VERSION "HNNBNNNYNNNNNNNNNNNNNNNNNNNNNNNNNNNNNNNNNN/4/%%%/4/'%**4NNN///"

NS_ :

BS_:

BU_: Airbag eCS

BO_ 64 Airbag_01: 8 Airbag
 SG_ Airbag_01_CRC : 0|8@1+ (1,0) [0|255] "" Vector__XXX
 SG_ Airbag_01_BZ : 8|4@1+ (1,0) [0|15] "" Vector__XXX
 SG_ AB_RGS_Anst : 12|4@1+ (1,0) [0|15] "" Vector__XXX
 SG_ AB_Front_Crash : 16|1@1+ (1,0) [0|1] "" Vector__XXX
 SG_ AB_Heck_Crash : 17|1@1+ (1,0) [0|1] "" Vector__XXX
 SG_ AB_SF_Crash : 18|1@1+ (1,0) [0|1] "" Vector__XXX
 SG_ AB_SB_Crash : 19|1@1+ (1,0) [0|1] "" Vector__XXX
 SG_ AB_Rollover_Crash : 20|1@1+ (1,0) [0|1] "" Vector__XXX
 SG_ AB_Crash_Int : 21|3@1+ (1,0) [0|7] ""  eCS
 SG_ AB_Lampe : 24|1@1+ (1,0) [0|1] "" Vector__XXX
 SG_ AB_Deaktiviert : 25|1@1+ (1,0) [0|1] "" Vector__XXX
 SG_ AB_VB_deaktiviert : 26|1@1+ (1,0) [0|1] "" Vector__XXX
 SG_ AB_Systemfehler : 27|1@1+ (1,0) [0|1] "" Vector__XXX
 SG_ AB_Diagnose : 28|1@1+ (1,0) [0|1] "" Vector__XXX
 SG_ AB_Stellgliedtest : 29|1@1+ (1,0) [0|1] "" Vector__XXX
 SG_ AB_Erh_Auf_VB : 30|2@1+ (1,0) [0|3] "" Vector__XXX
 SG_ AB_Gurtwarn_VF : 32|1@1+ (1,0) [0|1] "" Vector__XXX
 SG_ AB_Gurtwarn_VB : 33|1@1+ (1,0) [0|1] "" Vector__XXX
 SG_ AB_Anzeige_Fussg : 34|2@1+ (1,0) [0|3] "" Vector__XXX
 SG_ AB_Texte_AKS : 36|2@1+ (1,0) [0|3] "" Vector__XXX
 SG_ AB_PAO_Leuchte_Anf : 38|1@1+ (1,0) [0|1] "" Vector__XXX
 SG_ AB_MKB_gueltig : 39|1@1+ (1,0) [0|1] "" Vector__XXX
 SG_ AB_MKB_Anforderung : 40|1@1+ (1,0) [0|1] "" Vector__XXX
 SG_ AB_Versorgungsspannung : 41|1@1+ (1,0) [0|1] "" Vector__XXX
 SG_ AB_Deaktivierung_HV : 42|3@1+ (1,0) [0|7] "" Vector__XXX
 SG_ AB_EDR_Trigger : 45|2@1+ (1,0) [0|3] "" Vector__XXX
 SG_ AB_Belegung_VF : 47|2@1+ (1,0) [0|3] "" Vector__XXX
 SG_ AB_Gurtschloss_FA_ext : 49|3@1+ (1,0) [0|7] "" Vector__XXX
 SG_ AB_Gurtschloss_FA_ext_aktiv : 52|1@1+ (1,0) [0|1] "" Vector__XXX
 SG_ AB_eCS_Error : 53|1@1+ (1,0) [0|1] "" Vector__XXX
 SG_ ASM_Masterzeit_02 : 56|8@1+ (0.04,0) [0|10.16] "Unit_Secon" Vector__XXX

BO_ 1312 Airbag_02: 8 Airbag
 SG_ Airbag_02_CRC : 0|8@1+ (1,0) [0|255] "" Vector__XXX
 SG_ Airbag_02_BZ : 8|4@1+ (1,0) [0|15] "" Vector__XXX
 SG_ LoGeWa_Event_Kombiwarnung : 12|4@1+ (1,0) [0|15] "" Vector__XXX
 SG_ AB_Anforderung_eCall : 16|1@1+ (1,0) [0|1] "" Vector__XXX
 SG_ AB_Anprall_Seite_Beifahrer : 17|1@1+ (1,0) [0|1] "" Vector__XXX
 SG_ AB_Anprall_Rollover : 18|1@1+ (1,0) [0|1] "" Vector__XXX
 SG_ AB_Anprall_FGS : 19|1@1+ (1,0) [0|1] "" Vector__XXX
 SG_ AB_Anprall_Front_Beifahrer : 20|1@1+ (1,0) [0|1] "" Vector__XXX
 SG_ AB_Anprall_Front_Fahrer : 21|1@1+ (1,0) [0|1] "" Vector__XXX
 SG_ AB_Anprall_Heck_Beifahrer : 22|1@1+ (1,0) [0|1] "" Vector__XXX
 SG_ AB_Anprall_Heck_Fahrer : 23|1@1+ (1,0) [0|1] "" Vector__XXX
 SG_ AB_Wickelklappung_Reihe2_MI : 24|2@1+ (1,0) [0|3] "" Vector__XXX
 SG_ AB_Belegung_VB : 26|2@1+ (1,0) [0|3] "" Vector__XXX
 SG_ AB_Abschaltanf_SIH_BF : 28|1@1+ (1,0) [0|1] "" Vector__XXX
 SG_ AB_Anprall_Seite_Fahrer : 29|1@1+ (1,0) [0|1] "" Vector__XXX
 SG_ SC_PAO_Schriftzug_Anf : 30|2@1+ (1,0) [0|3] "" Vector__XXX
 SG_ SC_PAO_ON_Anf : 32|2@1+ (1,0) [0|3] "" Vector__XXX
 SG_ SC_PAO_OFF_Anf : 34|2@1+ (1,0) [0|3] "" Vector__XXX
 SG_ AB_Crashschwere : 36|3@1+ (1,0) [0|7] "" Vector__XXX
 SG_ AB_Anforderung_USM : 39|1@1+ (1,0) [0|1] "" Vector__XXX
 SG_ AB_Gurtschloss_FA : 40|2@1+ (1,0) [0|3] ""  eCS
 SG_ AB_Gurtschloss_BF : 42|2@1+ (1,0) [0|3] ""  eCS
 SG_ AB_Gurtschloss_Reihe2_FA : 44|2@1+ (1,0) [0|3] ""  eCS
 SG_ AB_Gurtschloss_Reihe2_MI : 46|2@1+ (1,0) [0|3] "" Vector__XXX
 SG_ AB_Gurtschloss_Reihe2_BF : 48|2@1+ (1,0) [0|3] ""  eCS
 SG_ AB_Gurtschloss_Reihe3_FA : 50|2@1+ (1,0) [0|3] ""  eCS
 SG_ AB_Gurtschloss_Reihe3_MI : 52|2@1+ (1,0) [0|3] "" Vector__XXX
 SG_ AB_Gurtschloss_Reihe3_BF : 54|2@1+ (1,0) [0|3] ""  eCS
 SG_ AB_Sitzpos_Sens_FA : 56|2@1+ (1,0) [0|3] "" Vector__XXX
 SG_ AB_Sitzpos_Sens_BF : 58|2@1+ (1,0) [0|3] "" Vector__XXX
 SG_ AB_Wickelklappung_Reihe2_BF : 60|2@1+ (1,0) [0|3] "" Vector__XXX
 SG_ AB_Wickelklappung_Reihe2_FA : 62|2@1+ (1,0) [0|3] "" Vector__XXX

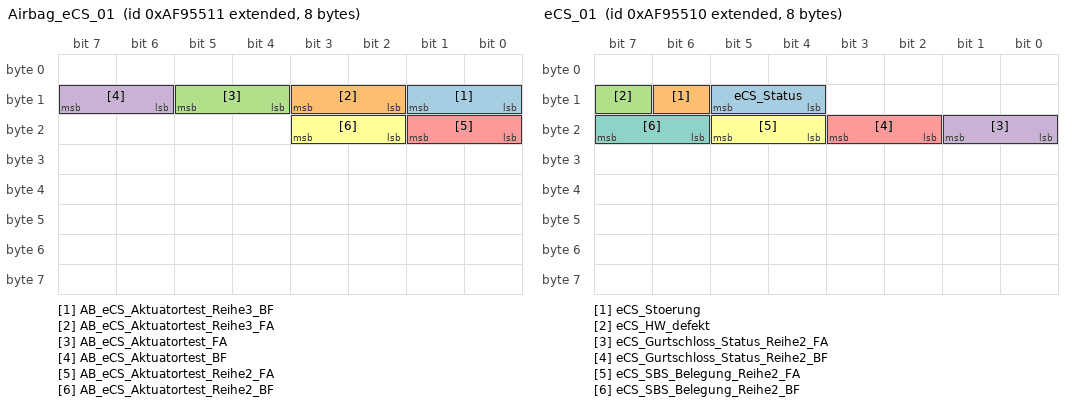
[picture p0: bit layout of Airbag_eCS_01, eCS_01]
BO_ 2331596049 Airbag_eCS_01: 8 Airbag
 SG_ AB_eCS_Aktuatortest_Reihe3_BF : 8|2@1+ (1,0) [0|3] ""  eCS
 SG_ AB_eCS_Aktuatortest_Reihe3_FA : 10|2@1+ (1,0) [0|3] ""  eCS
 SG_ AB_eCS_Aktuatortest_FA : 12|2@1+ (1,0) [0|3] ""  eCS
 SG_ AB_eCS_Aktuatortest_BF : 14|2@1+ (1,0) [0|3] ""  eCS
 SG_ AB_eCS_Aktuatortest_Reihe2_FA : 16|2@1+ (1,0) [0|3] ""  eCS
 SG_ AB_eCS_Aktuatortest_Reihe2_BF : 18|2@1+ (1,0) [0|3] ""  eCS

BO_ 2549891590 DIA_eCS_Req: 8 Airbag
 SG_ DIA_eCS_Req_Data : 0|64@1+ (1,0) [0|1.84467440737096E+019] ""  eCS

BO_ 2621456902 DIA_eCS_Req_FD: 64 Airbag
 SG_ DIA_eCS_Req_FD_Data : 0|512@1+ (1,0) [0|1.34078079299426E+154] ""  eCS

BO_ 2550022662 DIA_eCS_Resp: 8 eCS
 SG_ DIA_eCS_Resp_Data : 0|64@1+ (1,0) [0|1.84467440737096E+019] ""  Airbag

BO_ 2621587974 DIA_eCS_Resp_FD: 64 eCS
 SG_ DIA_eCS_Resp_FD_Data : 0|512@1+ (1,0) [0|1.34078079299426E+154] ""  Airbag

BO_ 2621460998 Diag_eCS_Req_FD: 64 Airbag
 SG_ Diag_eCS_Req_FD_Data : 0|512@1+ (1,0) [0|1.34078079299426E+154] ""  eCS

BO_ 2621592070 Diag_eCS_Resp_FD: 64 eCS
 SG_ Diag_eCS_Resp_FD_Data : 0|512@1+ (1,0) [0|1.34078079299426E+154] ""  Airbag

BO_ 2331596048 eCS_01: 8 eCS
 SG_ eCS_Status : 12|2@1+ (1,0) [0|3] ""  Airbag
 SG_ eCS_Stoerung : 14|1@1+ (1,0) [0|1] ""  Airbag
 SG_ eCS_HW_defekt : 15|1@1+ (1,0) [0|1] ""  Airbag
 SG_ eCS_Gurtschloss_Status_Reihe2_FA : 16|2@1+ (1,0) [0|3] ""  Airbag
 SG_ eCS_Gurtschloss_Status_Reihe2_BF : 18|2@1+ (1,0) [0|3] ""  Airbag
 SG_ eCS_SBS_Belegung_Reihe2_FA : 20|2@1+ (1,0) [0|3] ""  Airbag
 SG_ eCS_SBS_Belegung_Reihe2_BF : 22|2@1+ (1,0) [0|3] ""  Airbag

BO_ 2621469190 OBDC_SSN_eCS_Req_FD: 64 Airbag
 SG_ OBDC_SSN_eCS_Req_FD_Data : 0|512@1+ (1,0) [0|1.34078079299426E+154] ""  eCS

BO_ 2621600262 OBDC_SSN_eCS_Resp_FD: 64 eCS
 SG_ OBDC_SSN_eCS_Resp_FD_Data : 0|512@1+ (1,0) [0|1.34078079299426E+154] ""  Airbag

CM_ "Airbag_SUBCANFD_V14.08.02E Generated by BUSNETNG Produktiv 9.24.6";
CM_ BU_ Airbag "Airbag E3_Volumen";
CM_ SG_ 64 Airbag_01_CRC "Für MLB:
'Berechnung siehe Lastenheft 'Kommunikationsabsicherung für FlexRay und CAN''

Ab MQB und MLBevo:
'Berechnung siehe Lastenheft 'End-to-End Kommunikationsabsicherung''

Endwerte siehe Begleitdokument 'S-PDU Kennungsfolgen'";
CM_ SG_ 64 AB_RGS_Anst "PreCrash-Ansteuerung reversibler Gurtstraffer (Aktivierung und Kraftniveau)

10xx = deaktiviert";
CM_ SG_ 64 AB_Front_Crash "Bit wird bei Überschreitung der Gurtstraffer-, US- und RdW-Schwelle gesetzt";
CM_ SG_ 64 AB_Heck_Crash "Wird für alle neu anlaufenden Projekte umgesetzt: AB8.4, Audi8/VW8";
CM_ SG_ 64 AB_SF_Crash "Z.Zt. nur in Verbindung mit Crash-Intensität >= 100b (Kraftstoffpumpenabschaltung) verwendet.";
CM_ SG_ 64 AB_SB_Crash "Z.Zt. nur in Verbindung mit Crash-Intensität >= 100b (Kraftstoffpumpenabschaltung) verwendet.
";
CM_ SG_ 64 AB_Rollover_Crash "Wird im B6/B7 Cabrio und New Beetle Cabrio bedient. ";
CM_ SG_ 64 AB_Crash_Int "Crash_Intensität_1 = fahrzeugabhängige Reaktionen im Crash
Crash_Intensität_2 = fahrzeugabhängige Reaktionen im Crash
Crash_Intensität_3 = fahrzeugabhängige Reaktionen im Crash

Die jeweiligen fahrzeugabhängigen Reaktionen im Crash sind in einem separ";
CM_ SG_ 64 AB_Lampe "Sicherheitswarnlampe im Kombi wird vom Airbag-SG angesteuert; Zustand der Lampe wird auf dem CAN-Bus ausgegeben (auch Blinkinformation).";
CM_ SG_ 64 AB_Deaktiviert "Airbag oder Gurtstraffer wurden per Anpassung deaktiviert: Aktualisierung erst nach Selbsttest";
CM_ SG_ 64 AB_VB_deaktiviert "Als Option vorgehalten, Beifahrerairbag wurden per Schlüsselschalter oder Insassenerkennung deaktiviert";
CM_ SG_ 64 AB_Systemfehler "Systemfehler Ggf. wird Warnlampe dauernd eingeschaltet.";
CM_ SG_ 64 AB_Diagnose "Airbag in Diagnose";
CM_ SG_ 64 AB_Stellgliedtest "Information, ob Airbag im Stellgliedtest ist, um eine Notrufauflösung beim Stellgliedtest zu verhindern";
CM_ SG_ 64 AB_Erh_Auf_VB "Der Fahrer soll bei einem Statuswechsel des Beifahrerairbags (ausgelöst durch die Beifahrerinsassenerkennung oder den Schlüsselschloßschalter) aufmerksam gemacht werden durch eine Anzeige im Kombi. Nur Audi: gültig für: AB2 (4-Türer AU352), B7, C6, D3";
CM_ SG_ 64 AB_Gurtwarn_VF "Fahrer hat Gurt nicht gesteckt, Anzeige im Kombi";
CM_ SG_ 64 AB_Gurtwarn_VB "Beifahrer hat Gurt nicht gesteckt, Anzeige im Kombi";
CM_ SG_ 64 AB_Anzeige_Fussg "Anzeige für ausgelöste Fussgängerschutz-Aktuatorik";
CM_ SG_ 64 AB_Texte_AKS "Textanzeige für pyrotechnische Auslösung der aktiven Kopfstütze (AKS)";
CM_ SG_ 64 AB_PAO_Leuchte_Anf "Anforderung an die Passenger-Airbag-Off Leuchte in der Dachkonsole (ein / aus), Einsatz nur bei PAG";
CM_ SG_ 64 AB_MKB_gueltig "Multi-Kollisions-Bremsung im Airbag freigeschaltet";
CM_ SG_ 64 AB_MKB_Anforderung "Anforderung Multi-Kollisions-Bremsung";
CM_ SG_ 64 AB_Versorgungsspannung "Übertragung der Plausibilitätsinformation Kl.15-Last vs. Kl.15-CAN.
Bedienung im Fall Kl.15-Last 'EIN' und Kl.15-CAN 'AUS' mit Ausgabe Warnung/Akustik im Kombi.";
CM_ SG_ 64 AB_Deaktivierung_HV "Deaktivierung des HV-Systems und der HV-Teilnehmer im Crash (u.a. Hybrid- und Elektrofahrzeuge)";
CM_ SG_ 64 AB_EDR_Trigger "Triggerbedingung zur dezentralen Aufzeichnung unfallrelevanter Daten im Event Data Recorder";
CM_ SG_ 64 AB_Belegung_VF "Belegungserkennung vorne Fahrer.";
CM_ SG_ 64 AB_Gurtschloss_FA_ext "Das Ergebnis der Basisfunktion 'Plausibilisierung Gurtschloss' des Verlassenskonzepts wird im Signal dargestellt.";
CM_ SG_ 64 AB_Gurtschloss_FA_ext_aktiv "Über dieses Signal wird signalisiert ob die Erweiterte Gurtdiagnose (Ergebnis wird im Signal AB_Gurtschloss_FA_ext dargestellt) aktiviert oder deaktiviert ist.";
CM_ SG_ 64 AB_eCS_Error "Signal zur Anforderung der Anzeige von Störungen im System der elektrischen Gurtverriegelung";
CM_ SG_ 64 ASM_Masterzeit_02 "Masterzeit für alle ASM Sender";
CM_ SG_ 1312 Airbag_02_CRC "Für MLB:
'Berechnung siehe Lastenheft 'Kommunikationsabsicherung für FlexRay und CAN''

Ab MQB und MLBevo:
'Berechnung siehe Lastenheft 'End-to-End Kommunikationsabsicherung''

Endwerte siehe Begleitdokument 'S-PDU Kennungsfolgen'";
CM_ SG_ 1312 LoGeWa_Event_Kombiwarnung "Event für Kombiwarnung";
CM_ SG_ 1312 AB_Anforderung_eCall "Trigger für Car2X Steuergerät das ein eCall Ereignis erkannt wurde.";
CM_ SG_ 1312 AB_Anprall_Seite_Beifahrer "Uebermittlung der Lage einer Kollision, Anprallzone Beifahrerseite Seite";
CM_ SG_ 1312 AB_Anprall_Rollover "Uebermittlung der Lage einer Kollision, Rollover erkannt";
CM_ SG_ 1312 AB_Anprall_FGS "Uebermittlung der Lage einer Kollision, Fussgaengerschutz-Aktorik";
CM_ SG_ 1312 AB_Anprall_Front_Beifahrer "Uebermittlung der Lage einer Kollision, Anprallzone Front Beifahrerseite";
CM_ SG_ 1312 AB_Anprall_Front_Fahrer "Uebermittlung der Lage einer Kollision, Anprallzone Front Fahrerseite";
CM_ SG_ 1312 AB_Anprall_Heck_Beifahrer "Uebermittlung der Lage einer Kollision, Anprallzone Beifahrerseite hinten";
CM_ SG_ 1312 AB_Anprall_Heck_Fahrer "Uebermittlung der Lage einer Kollision, Anprallzone Fahrerseite hinten";
CM_ SG_ 1312 AB_Wickelklappung_Reihe2_MI "Status Wickelklappung 2. Reihe Mitte, Mehrausstattung";
CM_ SG_ 1312 AB_Belegung_VB "Belegungserkennung vorne Beifahrer. Wird in US-Steuergeräten über Bladder-Matte bedient, optional bei RdW, falls SBE_EuroNCAP entschieden wird.";
CM_ SG_ 1312 AB_Abschaltanf_SIH_BF "Die Insassenerkennung auf der Beifahrerseite fordert bei Übertemperatur eine Abschaltung der Sitzheizung an. Die Übertemperatur kann bei niederohmigen Nebenschlüssen der Sitzheizungsmatte als Folge von zu hohem resultierenden Strom auftreten.";
CM_ SG_ 1312 AB_Anprall_Seite_Fahrer "Uebermittlung der Lage einer Kollision, Anprallzone Fahrerseite Seite";
CM_ SG_ 1312 SC_PAO_Schriftzug_Anf "Sollwert für LED 'PASSENGER AIRBAG' in Anzeige Passenger Airbag On/Off";
CM_ SG_ 1312 SC_PAO_ON_Anf "Sollwert für LED 'ON' in Anzeige Passenger Airbag On/Off";
CM_ SG_ 1312 SC_PAO_OFF_Anf "Sollwert für LED 'OFF' in Anzeige Passenger Airbag On/Off";
CM_ SG_ 1312 AB_Crashschwere "Übermittlung der Crashschwere an das Gateway (OBDC)";
CM_ SG_ 1312 AB_Anforderung_USM "Trigger für Gateway (OBDC) und MIB/MMI, dass ein USM-Ereignis erkannt wurde.";
CM_ SG_ 1312 AB_Gurtschloss_FA "Gurtschlosstatatus Fahrerseite";
CM_ SG_ 1312 AB_Gurtschloss_BF "Gurtschlossstatus Beifahrerseite";
CM_ SG_ 1312 AB_Gurtschloss_Reihe2_FA "Gurtschlossstatus 2. Reihe Fahrerseite, Mehrausstattung";
CM_ SG_ 1312 AB_Gurtschloss_Reihe2_MI "Gurtschlossstatus 2. Reihe Mitte,  Mehrausstattung";
CM_ SG_ 1312 AB_Gurtschloss_Reihe2_BF "Gurtschlossstatus 2. Reihe Beifahrerseite,  Mehrausstattung";
CM_ SG_ 1312 AB_Gurtschloss_Reihe3_FA "Gurtschlossstatus 3. Reihe Fahrerseite,  Mehrausstattung";
CM_ SG_ 1312 AB_Gurtschloss_Reihe3_MI "Gurtschlossstatus 3. Reihe Mitte,  Mehrausstattung";
CM_ SG_ 1312 AB_Gurtschloss_Reihe3_BF "Gurtschlossstatus 3. Reihe Beifahrerseite,  Mehrausstattung";
CM_ SG_ 1312 AB_Sitzpos_Sens_FA "Ausgabe Sitzposition Fahrer";
CM_ SG_ 1312 AB_Sitzpos_Sens_BF "Ausgabe Sitzposition Beifahrer";
CM_ SG_ 1312 AB_Wickelklappung_Reihe2_BF "Status Wickelklappung 2. Reihe Beifahrerseite, Mehrausstattung";
CM_ SG_ 1312 AB_Wickelklappung_Reihe2_FA "Status Wickelklappung 2. Reihe Fahrerseite, Mehrausstattung";
CM_ SG_ 2331596049 AB_eCS_Aktuatortest_Reihe3_BF "Signal zum Stellgliedtest Sitz hinten in 3. SR Beifahrerseite";
CM_ SG_ 2331596049 AB_eCS_Aktuatortest_Reihe3_FA "Signal zum Stellgliedtest Sitz hinten in 3. SR Fahrerseite";
CM_ SG_ 2331596049 AB_eCS_Aktuatortest_FA "Signal zum Stellgliedtest Fahrersitz";
CM_ SG_ 2331596049 AB_eCS_Aktuatortest_BF "Signal zum Stellgliedtest Beifahrersitz";
CM_ SG_ 2331596049 AB_eCS_Aktuatortest_Reihe2_FA "Signal zum Stellgliedtest Sitz hinten in 2. SR Fahrerseite";
CM_ SG_ 2331596049 AB_eCS_Aktuatortest_Reihe2_BF "Signal zum Stellgliedtest Sitz hinten in 2. SR Beifahrerseite";
CM_ SG_ 2549891590 DIA_eCS_Req_Data "Diagnose Request Flashen <SG-Name>";
CM_ SG_ 2621456902 DIA_eCS_Req_FD_Data "Diagnose Request Flashen eCS";
CM_ SG_ 2550022662 DIA_eCS_Resp_Data "Diagnose Response Flashen <SG-Name>";
CM_ SG_ 2621587974 DIA_eCS_Resp_FD_Data "Diagnose Response Flashen eCS";
CM_ SG_ 2621460998 Diag_eCS_Req_FD_Data "UDS-Diagnose
ISO-TP Datenkanal - FID2NA
Request Funktion 0x07 Diagnosezugriff vom DK4-Master auf DK1/2-Knoten 0x742";
CM_ SG_ 2621592070 Diag_eCS_Resp_FD_Data "UDS-Diganose
ISO-TP Datenkanal - FID2NA
Response DK1/2-Knoten 0x742 an Funktion 0x07 Diagnosezugriff vom DK4-Master";
CM_ SG_ 2331596048 eCS_Status "Das eCS SG sendet den Status des Gurtband verriegelt oder entriegelt (Magnethub am Gurt gesperrt oder entsperrt)";
CM_ SG_ 2331596048 eCS_Stoerung "Das eCS signalisiert einen sporadischen Fehler oder einen Kommunikations-Timeout";
CM_ SG_ 2331596048 eCS_HW_defekt "das eCS signalisiert ein HW_defekt";
CM_ SG_ 2331596048 eCS_Gurtschloss_Status_Reihe2_FA "Das eCS SG sendet den Status des Gutschlosses 2.SR Fahrer an das Airbag SG";
CM_ SG_ 2331596048 eCS_Gurtschloss_Status_Reihe2_BF "Das eCS SG sendet den Status des Gutschlosses 2.SR Beifahrer an das Airbag SG";
CM_ SG_ 2331596048 eCS_SBS_Belegung_Reihe2_FA "Das eCS SG sendet den Status der Sitzbelegung 2.SR Fahrer an dem Airbag SG";
CM_ SG_ 2331596048 eCS_SBS_Belegung_Reihe2_BF "Das eCS SG sendet den Status der Sitzbelegung 2.SR Beifahrer an dem Airbag SG";
CM_ SG_ 2621469190 OBDC_SSN_eCS_Req_FD_Data "Request FID- zu NA- Kommunikation zw. OnboardDiagnoseClient und DK2F Sub-System";
CM_ SG_ 2621600262 OBDC_SSN_eCS_Resp_FD_Data "Response FID- zu NA- Kommunikation zw. OnboardDiagnoseClient und DK2F Sub-System";
BA_DEF_  "DBName" STRING ;
BA_DEF_  "GenNWMApBusSleep" STRING ;
BA_DEF_  "GenNWMApCanNormal" STRING ;
BA_DEF_  "GenNWMApCanOff" STRING ;
BA_DEF_  "GenNWMApCanOn" STRING ;
BA_DEF_  "GenNWMApCanSleep" STRING ;
BA_DEF_  "GenNWMApCanWakeUp" STRING ;
BA_DEF_  "GenNWMGotoMode_Awake" STRING ;
BA_DEF_  "GenNWMGotoMode_BusSleep" STRING ;
BA_DEF_  "GenNWMSleepTime" INT 0 1000000;
BA_DEF_  "GenNWMTalkNM" STRING ;
BA_DEF_  "Manufacturer" STRING ;
BA_DEF_  "NmhBaseAddress" HEX 0 536870911;
BA_DEF_  "NmhMessageCount" INT 0 1024;
BA_DEF_  "NmType" STRING ;
BA_DEF_  "VAGTP20_SetupMessageCount" INT 0 255;
BA_DEF_  "VAGTP20_SetupStartAddress" HEX 0 2047;
BA_DEF_  "VersionDay" INT 1 31;
BA_DEF_  "VersionMonth" INT 1 12;
BA_DEF_  "VersionWeek" INT 1 52;
BA_DEF_  "VersionYear" INT 0 99;
BA_DEF_  "VersionNumber" INT 0 65535;
BA_DEF_  "BusType" STRING ;
BA_DEF_  "Baudrate" INT 1 1000000;
BA_DEF_  "BaudrateCANFD" INT 1 16000000;
BA_DEF_  "NmhTimeoutTimer" INT 0 65535;
BA_DEF_  "NmhWaitBusSleepTimer" INT 0 65535;
BA_DEF_  "NmhPrepareBusSleepTimer" INT 0 65535;
BA_DEF_  "NmhLongTimer" INT 0 65535;
BA_DEF_  "NmhNStart" INT 0 255;
BA_DEF_ BU_  "GenNodAutoGenDsp" ENUM  "No","Yes";
BA_DEF_ BU_  "GenNodAutoGenSnd" ENUM  "No","Yes";
BA_DEF_ BU_  "GenNodSleepTime" INT 0 1000000;
BA_DEF_ BU_  "ILUsed" ENUM  "No","Yes";
BA_DEF_ BU_  "ECUVariantDefault" ENUM  "No","Yes";
BA_DEF_ BU_  "NodeLayerModules" STRING ;
BA_DEF_ BU_  "NmhNode" ENUM  "No","Yes";
BA_DEF_ BU_  "NmNode" ENUM  "No","Yes";
BA_DEF_ BU_  "SamplePointMin" FLOAT 50 99.9;
BA_DEF_ BU_  "SamplePointMax" FLOAT 50 99.9;
BA_DEF_ BU_  "SyncJumpWidthMin" FLOAT 0 50;
BA_DEF_ BU_  "SyncJumpWidthMax" FLOAT 0 50;
BA_DEF_ BU_  "SyncJumpWidthCANFDMin" FLOAT 0 50;
BA_DEF_ BU_  "SyncJumpWidthCANFDMax" FLOAT 0 50;
BA_DEF_ BU_  "SamplePointCANFDMin" FLOAT 50 99.9;
BA_DEF_ BU_  "SamplePointCANFDMax" FLOAT 50 99.9;
BA_DEF_ BU_  "SSPOffsetCANFDMin" FLOAT 50 99.9;
BA_DEF_ BU_  "SSPOffsetCANFDMax" FLOAT 50 99.9;
BA_DEF_ BU_  "TimeQuantaMin" INT 4 257;
BA_DEF_ BU_  "TimeQuantaMax" INT 4 257;
BA_DEF_ BU_  "TimeQuantaCANFDMin" INT 4 257;
BA_DEF_ BU_  "TimeQuantaCANFDMax" INT 4 257;
BA_DEF_ BO_  "DiagRequest" ENUM  "No","Yes";
BA_DEF_ BO_  "DiagResponse" ENUM  "No","Yes";
BA_DEF_ BO_  "DiagState" ENUM  "No","Yes";
BA_DEF_ BO_  "GenMsgChkConstant" HEX 0 4095;
BA_DEF_ BO_  "GenMsgCycleTime" INT 0 65535;
BA_DEF_ BO_  "GenMsgCycleTimeFast" INT 0 65535;
BA_DEF_ BO_  "GenMsgDelayTime" INT 0 100000;
BA_DEF_ BO_  "GenMsgILSupport" ENUM  "No","Yes";
BA_DEF_ BO_  "GenMsgNrOfRepetition" INT 0 100;
BA_DEF_ BO_  "GenMsgPDUConstants" STRING ;
BA_DEF_ BO_  "GenMsgSendType" ENUM  "Cyclic","not_used","not_used","not_used","not_used","not_used","not_used","IfActive","NoMsgSendType";
BA_DEF_ BO_  "GenMsgStartDelayTime" INT 0 100000;
BA_DEF_ BO_  "NmMessage" ENUM  "No","Yes";
BA_DEF_ BO_  "NmhMessage" ENUM  "No","Yes";
BA_DEF_ BO_  "MsgType" ENUM  "Application","NM ","NMH","TP2.0","ISO-TP ","BAP","EID","KS","XCP_PRE_CONFIGURED","XCP_RUNTIME_CONFIGURED";
BA_DEF_ BO_  "VAGTP20_API" HEX 0 255;
BA_DEF_ BO_  "VAGTP20_DynConnection" ENUM  "No","Yes";
BA_DEF_ BO_  "VAGTP20_DynSetup" ENUM  "No","Yes";
BA_DEF_ BO_  "VAGTP20_StatConnection" ENUM  "No","Yes";
BA_DEF_ BO_  "CANFD_BRS" ENUM  "0","1";
BA_DEF_ BO_  "VFrameFormat" ENUM  "StandardCAN","ExtendedCAN","reserved","reserved","reserved","reserved","reserved","reserved","reserved","reserved","reserved","reserved","reserved","reserved","StandardCAN_FD","ExtendedCAN_FD";
BA_DEF_ SG_  "GenSigActiveRepetitions" INT -2147483648 2147483647;
BA_DEF_ SG_  "GenSigSendType" ENUM  "Cyclic","OnWrite","OnWriteWithRepetition","OnChange","OnChangeWithRepetition","IfActive","IfActiveWithRepetition","NoSigSendType","OnChangeAndIfActive","OnChangeAndIfActiveWithRepetition";
BA_DEF_ SG_  "GenSigStartValue" INT -2147483648 2147483647;
BA_DEF_ SG_  "NWM-WakeupAllowed" ENUM  "No","Yes";
BA_DEF_ SG_  "GenSigFuncType" ENUM  "NoFunction","MsgCounter","CRC-8","XOR","XOR-2","DatedBit","SW-Kl15","CHK","Constant","Protocol","CRC-8-SAE_J1850","CRC-32","DataLength","DataID","MsgCounter16","SOK-Signatur","Cluster";
BA_DEF_ SG_  "GenSigSwitchedByIgnition" ENUM  "No","Yes";
BA_DEF_ SG_  "Fehlerwert" HEX 0 2147483647;
BA_DEF_ SG_  "GenSigMissingSourceValue" HEX 0 2147483647;
BA_DEF_REL_ BU_SG_REL_  "GenSigTimeoutTime" INT 0 65535;
BA_DEF_DEF_  "DBName" "";
BA_DEF_DEF_  "GenNWMApBusSleep" "";
BA_DEF_DEF_  "GenNWMApCanNormal" "";
BA_DEF_DEF_  "GenNWMApCanOff" "";
BA_DEF_DEF_  "GenNWMApCanOn" "";
BA_DEF_DEF_  "GenNWMApCanSleep" "";
BA_DEF_DEF_  "GenNWMApCanWakeUp" "";
BA_DEF_DEF_  "GenNWMGotoMode_Awake" "";
BA_DEF_DEF_  "GenNWMGotoMode_BusSleep" "";
BA_DEF_DEF_  "GenNWMSleepTime" 0;
BA_DEF_DEF_  "GenNWMTalkNM" "";
BA_DEF_DEF_  "Manufacturer" "";
BA_DEF_DEF_  "NmhBaseAddress" 0;
BA_DEF_DEF_  "NmhMessageCount" 1;
BA_DEF_DEF_  "NmType" "None";
BA_DEF_DEF_  "VAGTP20_SetupMessageCount" 0;
BA_DEF_DEF_  "VAGTP20_SetupStartAddress" 0;
BA_DEF_DEF_  "VersionDay" 19;
BA_DEF_DEF_  "VersionMonth" 8;
BA_DEF_DEF_  "VersionWeek" 34;
BA_DEF_DEF_  "VersionYear" 22;
BA_DEF_DEF_  "VersionNumber" 0;
BA_DEF_DEF_  "BusType" "";
BA_DEF_DEF_  "Baudrate" 500000;
BA_DEF_DEF_  "BaudrateCANFD" 2000000;
BA_DEF_DEF_  "NmhTimeoutTimer" 0;
BA_DEF_DEF_  "NmhWaitBusSleepTimer" 0;
BA_DEF_DEF_  "NmhPrepareBusSleepTimer" 0;
BA_DEF_DEF_  "NmhLongTimer" 0;
BA_DEF_DEF_  "NmhNStart" 0;
BA_DEF_DEF_  "GenNodAutoGenDsp" "Yes";
BA_DEF_DEF_  "GenNodAutoGenSnd" "Yes";
BA_DEF_DEF_  "GenNodSleepTime" 0;
BA_DEF_DEF_  "ILUsed" "Yes";
BA_DEF_DEF_  "ECUVariantDefault" "Yes";
BA_DEF_DEF_  "NodeLayerModules" "";
BA_DEF_DEF_  "NmhNode" "Yes";
BA_DEF_DEF_  "NmNode" "No";
BA_DEF_DEF_  "SamplePointMin" 75;
BA_DEF_DEF_  "SamplePointMax" 75;
BA_DEF_DEF_  "SyncJumpWidthMin" 50;
BA_DEF_DEF_  "SyncJumpWidthMax" 50;
BA_DEF_DEF_  "SyncJumpWidthCANFDMin" 50;
BA_DEF_DEF_  "SyncJumpWidthCANFDMax" 50;
BA_DEF_DEF_  "SamplePointCANFDMin" 75;
BA_DEF_DEF_  "SamplePointCANFDMax" 75;
BA_DEF_DEF_  "SSPOffsetCANFDMin" 75;
BA_DEF_DEF_  "SSPOffsetCANFDMax" 75;
BA_DEF_DEF_  "TimeQuantaMin" 160;
BA_DEF_DEF_  "TimeQuantaMax" 160;
BA_DEF_DEF_  "TimeQuantaCANFDMin" 40;
BA_DEF_DEF_  "TimeQuantaCANFDMax" 40;
BA_DEF_DEF_REL_ "GenSigTimeoutTime" 0;
BA_DEF_DEF_  "DiagRequest" "No";
BA_DEF_DEF_  "DiagResponse" "No";
BA_DEF_DEF_  "DiagState" "No";
BA_DEF_DEF_  "GenMsgChkConstant" 0;
BA_DEF_DEF_  "GenMsgCycleTime" 0;
BA_DEF_DEF_  "GenMsgCycleTimeFast" 0;
BA_DEF_DEF_  "GenMsgDelayTime" 0;
BA_DEF_DEF_  "GenMsgILSupport" "No";
BA_DEF_DEF_  "GenMsgNrOfRepetition" 0;
BA_DEF_DEF_  "GenMsgPDUConstants" "";
BA_DEF_DEF_  "GenMsgSendType" "NoMsgSendType";
BA_DEF_DEF_  "GenMsgStartDelayTime" 0;
BA_DEF_DEF_  "NmMessage" "No";
BA_DEF_DEF_  "NmhMessage" "No";
BA_DEF_DEF_  "MsgType" "Application";
BA_DEF_DEF_  "VAGTP20_API" 0;
BA_DEF_DEF_  "VAGTP20_DynConnection" "No";
BA_DEF_DEF_  "VAGTP20_DynSetup" "No";
BA_DEF_DEF_  "VAGTP20_StatConnection" "No";
BA_DEF_DEF_  "CANFD_BRS" "1";
BA_DEF_DEF_  "VFrameFormat" "StandardCAN";
BA_DEF_DEF_  "GenSigActiveRepetitions" 0;
BA_DEF_DEF_  "GenSigSendType" "NoSigSendType";
BA_DEF_DEF_  "GenSigStartValue" 0;
BA_DEF_DEF_  "NWM-WakeupAllowed" "No";
BA_DEF_DEF_  "GenSigFuncType" "NoFunction";
BA_DEF_DEF_  "GenSigSwitchedByIgnition" "Yes";
BA_DEF_DEF_  "Fehlerwert" 0;
BA_DEF_DEF_  "GenSigMissingSourceValue" 0;
BA_ "NmhNStart" 20;
BA_ "NmhLongTimer" 200;
BA_ "NmhPrepareBusSleepTimer" 500;
BA_ "NmhWaitBusSleepTimer" 750;
BA_ "NmhTimeoutTimer" 1000;
BA_ "BaudrateCANFD" 500000;
BA_ "BusType" "CAN FD";
BA_ "VersionNumber" 802;
BA_ "VAGTP20_SetupStartAddress" 512;
BA_ "VAGTP20_SetupMessageCount" 128;
BA_ "NmType" "NM-High";
BA_ "NmhMessageCount" 1024;
BA_ "NmhBaseAddress" 452984832;
BA_ "Manufacturer" "VAG";
BA_ "GenNWMTalkNM" "Nmh_ReqNetOn()";
BA_ "GenNWMSleepTime" 4000;
BA_ "GenNWMGotoMode_BusSleep" "Nmh_ReqNetOff()";
BA_ "GenNWMGotoMode_Awake" "Nmh_ReqNetOn()";
BA_ "GenNWMApCanWakeUp" "apCanWakeUp()";
BA_ "GenNWMApCanSleep" "apCanSleep()";
BA_ "GenNWMApCanOn" "NMIndnetOn()";
BA_ "GenNWMApCanOff" "NMIndnetOff()";
BA_ "GenNWMApCanNormal" "apCanNormal()";
BA_ "GenNWMApBusSleep" "NMIndNetSDN()";
BA_ "DBName" "Airbag_SUBCANFD";
BA_ "TimeQuantaCANFDMax" BU_ Airbag 20;
BA_ "TimeQuantaCANFDMin" BU_ Airbag 20;
BA_ "TimeQuantaMax" BU_ Airbag 20;
BA_ "TimeQuantaMin" BU_ Airbag 20;
BA_ "SSPOffsetCANFDMax" BU_ Airbag 80;
BA_ "SSPOffsetCANFDMin" BU_ Airbag 80;
BA_ "SamplePointCANFDMax" BU_ Airbag 80;
BA_ "SamplePointCANFDMin" BU_ Airbag 80;
BA_ "SyncJumpWidthCANFDMax" BU_ Airbag 20;
BA_ "SyncJumpWidthCANFDMin" BU_ Airbag 20;
BA_ "SyncJumpWidthMax" BU_ Airbag 20;
BA_ "SyncJumpWidthMin" BU_ Airbag 20;
BA_ "SamplePointMax" BU_ Airbag 80;
BA_ "SamplePointMin" BU_ Airbag 80;
BA_ "NodeLayerModules" BU_ Airbag "NMHigh.DLL";
BA_ "GenNodSleepTime" BU_ Airbag 4000;
BA_ "TimeQuantaCANFDMax" BU_ eCS 20;
BA_ "TimeQuantaCANFDMin" BU_ eCS 20;
BA_ "TimeQuantaMax" BU_ eCS 20;
BA_ "TimeQuantaMin" BU_ eCS 20;
BA_ "SSPOffsetCANFDMax" BU_ eCS 80;
BA_ "SSPOffsetCANFDMin" BU_ eCS 80;
BA_ "SamplePointCANFDMax" BU_ eCS 80;
BA_ "SamplePointCANFDMin" BU_ eCS 80;
BA_ "SyncJumpWidthCANFDMax" BU_ eCS 20;
BA_ "SyncJumpWidthCANFDMin" BU_ eCS 20;
BA_ "SyncJumpWidthMax" BU_ eCS 20;
BA_ "SyncJumpWidthMin" BU_ eCS 20;
BA_ "SamplePointMax" BU_ eCS 80;
BA_ "SamplePointMin" BU_ eCS 80;
BA_ "NmhNode" BU_ eCS 0;
BA_ "GenNodSleepTime" BU_ eCS 4000;
BA_ "CANFD_BRS" BO_ 64 0;
BA_ "GenMsgSendType" BO_ 64 0;
BA_ "GenMsgPDUConstants" BO_ 64 "0x40,0x40,0x40,0x40,0x40,0x40,0x40,0x40,0x40,0x40,0x40,0x40,0x40,0x40,0x40,0x40";
BA_ "GenMsgNrOfRepetition" BO_ 64 5;
BA_ "GenMsgILSupport" BO_ 64 1;
BA_ "GenMsgDelayTime" BO_ 64 10;
BA_ "GenMsgCycleTimeFast" BO_ 64 10;
BA_ "GenMsgCycleTime" BO_ 64 40;
BA_ "GenMsgChkConstant" BO_ 64 64;
BA_ "VFrameFormat" BO_ 64 14;
BA_ "CANFD_BRS" BO_ 1312 0;
BA_ "GenMsgSendType" BO_ 1312 0;
BA_ "GenMsgPDUConstants" BO_ 1312 "0x44,0x44,0x44,0x44,0x44,0x44,0x44,0x44,0x44,0x44,0x44,0x44,0x44,0x44,0x44,0x44";
BA_ "GenMsgILSupport" BO_ 1312 1;
BA_ "GenMsgDelayTime" BO_ 1312 20;
BA_ "GenMsgCycleTime" BO_ 1312 200;
BA_ "GenMsgChkConstant" BO_ 1312 68;
BA_ "VFrameFormat" BO_ 1312 14;
BA_ "CANFD_BRS" BO_ 2331596049 0;
BA_ "GenMsgSendType" BO_ 2331596049 0;
BA_ "GenMsgILSupport" BO_ 2331596049 1;
BA_ "GenMsgCycleTime" BO_ 2331596049 50;
BA_ "VFrameFormat" BO_ 2331596049 15;
BA_ "CANFD_BRS" BO_ 2549891590 0;
BA_ "MsgType" BO_ 2549891590 4;
BA_ "DiagRequest" BO_ 2549891590 1;
BA_ "VFrameFormat" BO_ 2549891590 15;
BA_ "CANFD_BRS" BO_ 2621456902 0;
BA_ "MsgType" BO_ 2621456902 4;
BA_ "DiagRequest" BO_ 2621456902 1;
BA_ "VFrameFormat" BO_ 2621456902 15;
BA_ "CANFD_BRS" BO_ 2550022662 0;
BA_ "MsgType" BO_ 2550022662 4;
BA_ "DiagResponse" BO_ 2550022662 1;
BA_ "VFrameFormat" BO_ 2550022662 15;
BA_ "CANFD_BRS" BO_ 2621587974 0;
BA_ "MsgType" BO_ 2621587974 4;
BA_ "DiagResponse" BO_ 2621587974 1;
BA_ "VFrameFormat" BO_ 2621587974 15;
BA_ "CANFD_BRS" BO_ 2621460998 0;
BA_ "MsgType" BO_ 2621460998 4;
BA_ "DiagRequest" BO_ 2621460998 1;
BA_ "VFrameFormat" BO_ 2621460998 15;
BA_ "CANFD_BRS" BO_ 2621592070 0;
BA_ "MsgType" BO_ 2621592070 4;
BA_ "DiagResponse" BO_ 2621592070 1;
BA_ "VFrameFormat" BO_ 2621592070 15;
BA_ "CANFD_BRS" BO_ 2331596048 0;
BA_ "GenMsgSendType" BO_ 2331596048 0;
BA_ "GenMsgILSupport" BO_ 2331596048 1;
BA_ "GenMsgCycleTime" BO_ 2331596048 50;
BA_ "VFrameFormat" BO_ 2331596048 15;
BA_ "CANFD_BRS" BO_ 2621469190 0;
BA_ "MsgType" BO_ 2621469190 4;
BA_ "DiagRequest" BO_ 2621469190 1;
BA_ "VFrameFormat" BO_ 2621469190 15;
BA_ "CANFD_BRS" BO_ 2621600262 0;
BA_ "MsgType" BO_ 2621600262 4;
BA_ "DiagResponse" BO_ 2621600262 1;
BA_ "VFrameFormat" BO_ 2621600262 15;
BA_ "GenSigSwitchedByIgnition" SG_ 64 Airbag_01_CRC 0;
BA_ "GenSigFuncType" SG_ 64 Airbag_01_CRC 2;
BA_ "GenSigSendType" SG_ 64 Airbag_01_CRC 0;
BA_ "GenSigSwitchedByIgnition" SG_ 64 Airbag_01_BZ 0;
BA_ "GenSigFuncType" SG_ 64 Airbag_01_BZ 1;
BA_ "GenSigSendType" SG_ 64 Airbag_01_BZ 0;
BA_ "GenSigSwitchedByIgnition" SG_ 64 AB_RGS_Anst 0;
BA_ "GenSigStartValue" SG_ 64 AB_RGS_Anst 8;
BA_ "GenSigSendType" SG_ 64 AB_RGS_Anst 3;
BA_ "GenSigSwitchedByIgnition" SG_ 64 AB_Front_Crash 0;
BA_ "GenSigSendType" SG_ 64 AB_Front_Crash 4;
BA_ "GenSigSwitchedByIgnition" SG_ 64 AB_Heck_Crash 0;
BA_ "GenSigSendType" SG_ 64 AB_Heck_Crash 4;
BA_ "GenSigSwitchedByIgnition" SG_ 64 AB_SF_Crash 0;
BA_ "GenSigSendType" SG_ 64 AB_SF_Crash 4;
BA_ "GenSigSwitchedByIgnition" SG_ 64 AB_SB_Crash 0;
BA_ "GenSigSendType" SG_ 64 AB_SB_Crash 4;
BA_ "GenSigSwitchedByIgnition" SG_ 64 AB_Rollover_Crash 0;
BA_ "GenSigSendType" SG_ 64 AB_Rollover_Crash 4;
BA_ "GenSigSwitchedByIgnition" SG_ 64 AB_Crash_Int 0;
BA_ "GenSigSendType" SG_ 64 AB_Crash_Int 4;
BA_ "GenSigSwitchedByIgnition" SG_ 64 AB_Lampe 0;
BA_ "GenSigStartValue" SG_ 64 AB_Lampe 1;
BA_ "GenSigSendType" SG_ 64 AB_Lampe 0;
BA_ "GenSigSwitchedByIgnition" SG_ 64 AB_Deaktiviert 0;
BA_ "GenSigSendType" SG_ 64 AB_Deaktiviert 0;
BA_ "GenSigSwitchedByIgnition" SG_ 64 AB_VB_deaktiviert 0;
BA_ "GenSigStartValue" SG_ 64 AB_VB_deaktiviert 1;
BA_ "GenSigSendType" SG_ 64 AB_VB_deaktiviert 0;
BA_ "GenSigSwitchedByIgnition" SG_ 64 AB_Systemfehler 0;
BA_ "GenSigSendType" SG_ 64 AB_Systemfehler 0;
BA_ "GenSigSwitchedByIgnition" SG_ 64 AB_Diagnose 0;
BA_ "GenSigSendType" SG_ 64 AB_Diagnose 0;
BA_ "GenSigSwitchedByIgnition" SG_ 64 AB_Stellgliedtest 0;
BA_ "GenSigSendType" SG_ 64 AB_Stellgliedtest 0;
BA_ "GenSigSwitchedByIgnition" SG_ 64 AB_Erh_Auf_VB 0;
BA_ "GenSigSendType" SG_ 64 AB_Erh_Auf_VB 0;
BA_ "GenSigSwitchedByIgnition" SG_ 64 AB_Gurtwarn_VF 0;
BA_ "GenSigSendType" SG_ 64 AB_Gurtwarn_VF 0;
BA_ "GenSigSwitchedByIgnition" SG_ 64 AB_Gurtwarn_VB 0;
BA_ "GenSigSendType" SG_ 64 AB_Gurtwarn_VB 0;
BA_ "GenSigSwitchedByIgnition" SG_ 64 AB_Anzeige_Fussg 0;
BA_ "GenSigSendType" SG_ 64 AB_Anzeige_Fussg 0;
BA_ "GenSigSwitchedByIgnition" SG_ 64 AB_Texte_AKS 0;
BA_ "GenSigSendType" SG_ 64 AB_Texte_AKS 0;
BA_ "GenSigSwitchedByIgnition" SG_ 64 AB_PAO_Leuchte_Anf 0;
BA_ "GenSigStartValue" SG_ 64 AB_PAO_Leuchte_Anf 1;
BA_ "GenSigSendType" SG_ 64 AB_PAO_Leuchte_Anf 0;
BA_ "GenSigSwitchedByIgnition" SG_ 64 AB_MKB_gueltig 0;
BA_ "GenSigSendType" SG_ 64 AB_MKB_gueltig 0;
BA_ "GenSigSwitchedByIgnition" SG_ 64 AB_MKB_Anforderung 0;
BA_ "GenSigSendType" SG_ 64 AB_MKB_Anforderung 4;
BA_ "GenSigSwitchedByIgnition" SG_ 64 AB_Versorgungsspannung 0;
BA_ "GenSigSendType" SG_ 64 AB_Versorgungsspannung 0;
BA_ "Fehlerwert" SG_ 64 AB_Deaktivierung_HV 7;
BA_ "GenSigSwitchedByIgnition" SG_ 64 AB_Deaktivierung_HV 0;
BA_ "GenSigSendType" SG_ 64 AB_Deaktivierung_HV 4;
BA_ "GenSigSwitchedByIgnition" SG_ 64 AB_EDR_Trigger 0;
BA_ "GenSigSendType" SG_ 64 AB_EDR_Trigger 3;
BA_ "Fehlerwert" SG_ 64 AB_Belegung_VF 1;
BA_ "GenSigSwitchedByIgnition" SG_ 64 AB_Belegung_VF 0;
BA_ "GenSigSendType" SG_ 64 AB_Belegung_VF 0;
BA_ "Fehlerwert" SG_ 64 AB_Gurtschloss_FA_ext 7;
BA_ "GenSigSwitchedByIgnition" SG_ 64 AB_Gurtschloss_FA_ext 0;
BA_ "GenSigStartValue" SG_ 64 AB_Gurtschloss_FA_ext 6;
BA_ "GenSigSendType" SG_ 64 AB_Gurtschloss_FA_ext 3;
BA_ "GenSigSwitchedByIgnition" SG_ 64 AB_Gurtschloss_FA_ext_aktiv 0;
BA_ "GenSigSendType" SG_ 64 AB_Gurtschloss_FA_ext_aktiv 0;
BA_ "GenSigSwitchedByIgnition" SG_ 64 AB_eCS_Error 0;
BA_ "GenSigSendType" SG_ 64 AB_eCS_Error 0;
BA_ "GenSigSwitchedByIgnition" SG_ 64 ASM_Masterzeit_02 0;
BA_ "GenSigStartValue" SG_ 64 ASM_Masterzeit_02 255;
BA_ "GenSigSendType" SG_ 64 ASM_Masterzeit_02 0;
BA_ "GenSigSwitchedByIgnition" SG_ 1312 Airbag_02_CRC 0;
BA_ "GenSigFuncType" SG_ 1312 Airbag_02_CRC 2;
BA_ "GenSigSendType" SG_ 1312 Airbag_02_CRC 0;
BA_ "GenSigSwitchedByIgnition" SG_ 1312 Airbag_02_BZ 0;
BA_ "GenSigFuncType" SG_ 1312 Airbag_02_BZ 1;
BA_ "GenSigSendType" SG_ 1312 Airbag_02_BZ 0;
BA_ "GenSigSwitchedByIgnition" SG_ 1312 LoGeWa_Event_Kombiwarnung 0;
BA_ "GenSigSendType" SG_ 1312 LoGeWa_Event_Kombiwarnung 3;
BA_ "GenSigSwitchedByIgnition" SG_ 1312 AB_Anforderung_eCall 0;
BA_ "GenSigSendType" SG_ 1312 AB_Anforderung_eCall 0;
BA_ "GenSigSendType" SG_ 1312 AB_Anprall_Seite_Beifahrer 3;
BA_ "GenSigSendType" SG_ 1312 AB_Anprall_Rollover 3;
BA_ "GenSigSendType" SG_ 1312 AB_Anprall_FGS 3;
BA_ "GenSigSendType" SG_ 1312 AB_Anprall_Front_Beifahrer 3;
BA_ "GenSigSendType" SG_ 1312 AB_Anprall_Front_Fahrer 3;
BA_ "GenSigSendType" SG_ 1312 AB_Anprall_Heck_Beifahrer 3;
BA_ "GenSigSendType" SG_ 1312 AB_Anprall_Heck_Fahrer 3;
BA_ "GenSigSwitchedByIgnition" SG_ 1312 AB_Wickelklappung_Reihe2_MI 0;
BA_ "GenSigStartValue" SG_ 1312 AB_Wickelklappung_Reihe2_MI 1;
BA_ "GenSigSendType" SG_ 1312 AB_Wickelklappung_Reihe2_MI 3;
BA_ "Fehlerwert" SG_ 1312 AB_Belegung_VB 1;
BA_ "GenSigSwitchedByIgnition" SG_ 1312 AB_Belegung_VB 0;
BA_ "GenSigSendType" SG_ 1312 AB_Belegung_VB 0;
BA_ "GenSigSendType" SG_ 1312 AB_Abschaltanf_SIH_BF 3;
BA_ "GenSigSendType" SG_ 1312 AB_Anprall_Seite_Fahrer 3;
BA_ "GenSigSwitchedByIgnition" SG_ 1312 SC_PAO_Schriftzug_Anf 0;
BA_ "GenSigSendType" SG_ 1312 SC_PAO_Schriftzug_Anf 3;
BA_ "GenSigSwitchedByIgnition" SG_ 1312 SC_PAO_ON_Anf 0;
BA_ "GenSigSendType" SG_ 1312 SC_PAO_ON_Anf 3;
BA_ "GenSigSwitchedByIgnition" SG_ 1312 SC_PAO_OFF_Anf 0;
BA_ "GenSigSendType" SG_ 1312 SC_PAO_OFF_Anf 3;
BA_ "Fehlerwert" SG_ 1312 AB_Crashschwere 7;
BA_ "GenSigSwitchedByIgnition" SG_ 1312 AB_Crashschwere 0;
BA_ "GenSigSendType" SG_ 1312 AB_Crashschwere 3;
BA_ "GenSigSwitchedByIgnition" SG_ 1312 AB_Anforderung_USM 0;
BA_ "GenSigSendType" SG_ 1312 AB_Anforderung_USM 0;
BA_ "GenSigSwitchedByIgnition" SG_ 1312 AB_Gurtschloss_FA 0;
BA_ "GenSigStartValue" SG_ 1312 AB_Gurtschloss_FA 1;
BA_ "GenSigSendType" SG_ 1312 AB_Gurtschloss_FA 3;
BA_ "GenSigSwitchedByIgnition" SG_ 1312 AB_Gurtschloss_BF 0;
BA_ "GenSigStartValue" SG_ 1312 AB_Gurtschloss_BF 1;
BA_ "GenSigSendType" SG_ 1312 AB_Gurtschloss_BF 3;
BA_ "GenSigSwitchedByIgnition" SG_ 1312 AB_Gurtschloss_Reihe2_FA 0;
BA_ "GenSigStartValue" SG_ 1312 AB_Gurtschloss_Reihe2_FA 1;
BA_ "GenSigSendType" SG_ 1312 AB_Gurtschloss_Reihe2_FA 3;
BA_ "GenSigSwitchedByIgnition" SG_ 1312 AB_Gurtschloss_Reihe2_MI 0;
BA_ "GenSigStartValue" SG_ 1312 AB_Gurtschloss_Reihe2_MI 1;
BA_ "GenSigSendType" SG_ 1312 AB_Gurtschloss_Reihe2_MI 3;
BA_ "GenSigSwitchedByIgnition" SG_ 1312 AB_Gurtschloss_Reihe2_BF 0;
BA_ "GenSigStartValue" SG_ 1312 AB_Gurtschloss_Reihe2_BF 1;
BA_ "GenSigSendType" SG_ 1312 AB_Gurtschloss_Reihe2_BF 3;
BA_ "GenSigSwitchedByIgnition" SG_ 1312 AB_Gurtschloss_Reihe3_FA 0;
BA_ "GenSigStartValue" SG_ 1312 AB_Gurtschloss_Reihe3_FA 1;
BA_ "GenSigSendType" SG_ 1312 AB_Gurtschloss_Reihe3_FA 3;
BA_ "GenSigSwitchedByIgnition" SG_ 1312 AB_Gurtschloss_Reihe3_MI 0;
BA_ "GenSigStartValue" SG_ 1312 AB_Gurtschloss_Reihe3_MI 1;
BA_ "GenSigSendType" SG_ 1312 AB_Gurtschloss_Reihe3_MI 3;
BA_ "GenSigSwitchedByIgnition" SG_ 1312 AB_Gurtschloss_Reihe3_BF 0;
BA_ "GenSigStartValue" SG_ 1312 AB_Gurtschloss_Reihe3_BF 1;
BA_ "GenSigSendType" SG_ 1312 AB_Gurtschloss_Reihe3_BF 3;
BA_ "Fehlerwert" SG_ 1312 AB_Sitzpos_Sens_FA 1;
BA_ "GenSigSwitchedByIgnition" SG_ 1312 AB_Sitzpos_Sens_FA 0;
BA_ "GenSigSendType" SG_ 1312 AB_Sitzpos_Sens_FA 0;
BA_ "Fehlerwert" SG_ 1312 AB_Sitzpos_Sens_BF 1;
BA_ "GenSigSwitchedByIgnition" SG_ 1312 AB_Sitzpos_Sens_BF 0;
BA_ "GenSigSendType" SG_ 1312 AB_Sitzpos_Sens_BF 0;
BA_ "GenSigSwitchedByIgnition" SG_ 1312 AB_Wickelklappung_Reihe2_BF 0;
BA_ "GenSigStartValue" SG_ 1312 AB_Wickelklappung_Reihe2_BF 1;
BA_ "GenSigSendType" SG_ 1312 AB_Wickelklappung_Reihe2_BF 3;
BA_ "GenSigSwitchedByIgnition" SG_ 1312 AB_Wickelklappung_Reihe2_FA 0;
BA_ "GenSigStartValue" SG_ 1312 AB_Wickelklappung_Reihe2_FA 1;
BA_ "GenSigSendType" SG_ 1312 AB_Wickelklappung_Reihe2_FA 3;
BA_ "GenSigSendType" SG_ 2331596049 AB_eCS_Aktuatortest_Reihe3_BF 0;
BA_ "GenSigSendType" SG_ 2331596049 AB_eCS_Aktuatortest_Reihe3_FA 0;
BA_ "GenSigSendType" SG_ 2331596049 AB_eCS_Aktuatortest_FA 0;
BA_ "GenSigSendType" SG_ 2331596049 AB_eCS_Aktuatortest_BF 0;
BA_ "GenSigSendType" SG_ 2331596049 AB_eCS_Aktuatortest_Reihe2_FA 0;
BA_ "GenSigSendType" SG_ 2331596049 AB_eCS_Aktuatortest_Reihe2_BF 0;
BA_ "GenSigSwitchedByIgnition" SG_ 2549891590 DIA_eCS_Req_Data 0;
BA_ "GenSigFuncType" SG_ 2549891590 DIA_eCS_Req_Data 9;
BA_ "GenSigSendType" SG_ 2549891590 DIA_eCS_Req_Data 3;
BA_ "GenSigSwitchedByIgnition" SG_ 2621456902 DIA_eCS_Req_FD_Data 0;
BA_ "GenSigFuncType" SG_ 2621456902 DIA_eCS_Req_FD_Data 9;
BA_ "GenSigSendType" SG_ 2621456902 DIA_eCS_Req_FD_Data 3;
BA_ "GenSigSwitchedByIgnition" SG_ 2550022662 DIA_eCS_Resp_Data 0;
BA_ "GenSigFuncType" SG_ 2550022662 DIA_eCS_Resp_Data 9;
BA_ "GenSigSendType" SG_ 2550022662 DIA_eCS_Resp_Data 3;
BA_ "GenSigSwitchedByIgnition" SG_ 2621587974 DIA_eCS_Resp_FD_Data 0;
BA_ "GenSigFuncType" SG_ 2621587974 DIA_eCS_Resp_FD_Data 9;
BA_ "GenSigSendType" SG_ 2621587974 DIA_eCS_Resp_FD_Data 3;
BA_ "GenSigSwitchedByIgnition" SG_ 2621460998 Diag_eCS_Req_FD_Data 0;
BA_ "GenSigFuncType" SG_ 2621460998 Diag_eCS_Req_FD_Data 9;
BA_ "GenSigSendType" SG_ 2621460998 Diag_eCS_Req_FD_Data 3;
BA_ "GenSigSwitchedByIgnition" SG_ 2621592070 Diag_eCS_Resp_FD_Data 0;
BA_ "GenSigFuncType" SG_ 2621592070 Diag_eCS_Resp_FD_Data 9;
BA_ "GenSigSendType" SG_ 2621592070 Diag_eCS_Resp_FD_Data 3;
BA_ "Fehlerwert" SG_ 2331596048 eCS_Status 3;
BA_ "GenSigSendType" SG_ 2331596048 eCS_Status 0;
BA_ "GenSigSendType" SG_ 2331596048 eCS_Stoerung 0;
BA_ "GenSigSendType" SG_ 2331596048 eCS_HW_defekt 0;
BA_ "GenSigStartValue" SG_ 2331596048 eCS_Gurtschloss_Status_Reihe2_FA 1;
BA_ "GenSigSendType" SG_ 2331596048 eCS_Gurtschloss_Status_Reihe2_FA 0;
BA_ "GenSigStartValue" SG_ 2331596048 eCS_Gurtschloss_Status_Reihe2_BF 1;
BA_ "GenSigSendType" SG_ 2331596048 eCS_Gurtschloss_Status_Reihe2_BF 0;
BA_ "GenSigStartValue" SG_ 2331596048 eCS_SBS_Belegung_Reihe2_FA 2;
BA_ "GenSigSendType" SG_ 2331596048 eCS_SBS_Belegung_Reihe2_FA 0;
BA_ "GenSigStartValue" SG_ 2331596048 eCS_SBS_Belegung_Reihe2_BF 2;
BA_ "GenSigSendType" SG_ 2331596048 eCS_SBS_Belegung_Reihe2_BF 0;
BA_ "GenSigSwitchedByIgnition" SG_ 2621469190 OBDC_SSN_eCS_Req_FD_Data 0;
BA_ "GenSigFuncType" SG_ 2621469190 OBDC_SSN_eCS_Req_FD_Data 9;
BA_ "GenSigSendType" SG_ 2621469190 OBDC_SSN_eCS_Req_FD_Data 3;
BA_ "GenSigSwitchedByIgnition" SG_ 2621600262 OBDC_SSN_eCS_Resp_FD_Data 0;
BA_ "GenSigFuncType" SG_ 2621600262 OBDC_SSN_eCS_Resp_FD_Data 9;
BA_ "GenSigSendType" SG_ 2621600262 OBDC_SSN_eCS_Resp_FD_Data 3;
BA_REL_ "GenSigTimeoutTime" BU_SG_REL_ eCS SG_ 64 AB_Crash_Int 500;
BA_REL_ "GenSigTimeoutTime" BU_SG_REL_ eCS SG_ 1312 AB_Gurtschloss_FA 2000;
BA_REL_ "GenSigTimeoutTime" BU_SG_REL_ eCS SG_ 1312 AB_Gurtschloss_BF 2000;
BA_REL_ "GenSigTimeoutTime" BU_SG_REL_ eCS SG_ 1312 AB_Gurtschloss_Reihe2_FA 2000;
BA_REL_ "GenSigTimeoutTime" BU_SG_REL_ eCS SG_ 1312 AB_Gurtschloss_Reihe2_BF 2000;
BA_REL_ "GenSigTimeoutTime" BU_SG_REL_ eCS SG_ 1312 AB_Gurtschloss_Reihe3_FA 2000;
BA_REL_ "GenSigTimeoutTime" BU_SG_REL_ eCS SG_ 1312 AB_Gurtschloss_Reihe3_BF 2000;
BA_REL_ "GenSigTimeoutTime" BU_SG_REL_ eCS SG_ 2331596049 AB_eCS_Aktuatortest_Reihe3_BF 500;
BA_REL_ "GenSigTimeoutTime" BU_SG_REL_ eCS SG_ 2331596049 AB_eCS_Aktuatortest_Reihe3_FA 500;
BA_REL_ "GenSigTimeoutTime" BU_SG_REL_ eCS SG_ 2331596049 AB_eCS_Aktuatortest_FA 500;
BA_REL_ "GenSigTimeoutTime" BU_SG_REL_ eCS SG_ 2331596049 AB_eCS_Aktuatortest_BF 500;
BA_REL_ "GenSigTimeoutTime" BU_SG_REL_ eCS SG_ 2331596049 AB_eCS_Aktuatortest_Reihe2_FA 500;
BA_REL_ "GenSigTimeoutTime" BU_SG_REL_ eCS SG_ 2331596049 AB_eCS_Aktuatortest_Reihe2_BF 500;
BA_REL_ "GenSigTimeoutTime" BU_SG_REL_ Airbag SG_ 2331596048 eCS_Status 500;
BA_REL_ "GenSigTimeoutTime" BU_SG_REL_ Airbag SG_ 2331596048 eCS_Stoerung 500;
BA_REL_ "GenSigTimeoutTime" BU_SG_REL_ Airbag SG_ 2331596048 eCS_HW_defekt 500;
BA_REL_ "GenSigTimeoutTime" BU_SG_REL_ Airbag SG_ 2331596048 eCS_Gurtschloss_Status_Reihe2_FA 500;
BA_REL_ "GenSigTimeoutTime" BU_SG_REL_ Airbag SG_ 2331596048 eCS_Gurtschloss_Status_Reihe2_BF 500;
BA_REL_ "GenSigTimeoutTime" BU_SG_REL_ Airbag SG_ 2331596048 eCS_SBS_Belegung_Reihe2_FA 500;
BA_REL_ "GenSigTimeoutTime" BU_SG_REL_ Airbag SG_ 2331596048 eCS_SBS_Belegung_Reihe2_BF 500;
VAL_ 64 AB_RGS_Anst 4 "aktiv_Niveau_1" 5 "aktiv_Niveau_2" 6 "aktiv_Niveau_3" 7 "aktiv_Niveau_4" 8 "deaktiviert" ;
VAL_ 64 AB_Front_Crash 0 "kein_Front_Crash" 1 "Front_Crash" ;
VAL_ 64 AB_Heck_Crash 0 "kein_Heck_Crash" 1 "Heck_Crash" ;
VAL_ 64 AB_SF_Crash 0 "kein_Seiten_Crash_Fahrer" 1 "Seiten_Crash_Fahrer" ;
VAL_ 64 AB_SB_Crash 0 "kein_Seiten_Crash_Beifahrer" 1 "Seiten_Crash_Beifahrer" ;
VAL_ 64 AB_Rollover_Crash 0 "kein_Rollover" 1 "Rollover" ;
VAL_ 64 AB_Crash_Int 0 "kein_Crash" 1 "Crash_Intensitaet_1" 2 "Crash_Intensitaet_2_(nur_Stellgliedtest_MLB_B8)" 3 "Crash_Intensitaet_2_(nur_D4_C7_Colorado_NF_PAG__Crash_im_MLB_B8)" 4 "Crash_Intensitaet_3_(alt_VW/AUDI__Stellgliedtest_MLB_B8)" 5 "Crash_Intensitaet_3_(alt_PAG)" 7 "Crash_Intensitaet_3" ;
VAL_ 64 AB_Lampe 0 "Aus" 1 "Ein" ;
VAL_ 64 AB_Deaktiviert 0 "aktiv" 1 "deaktiviert" ;
VAL_ 64 AB_VB_deaktiviert 0 "Beifahrerairbag_aktiv" 1 "Beifahrerairbag_deaktiviert" ;
VAL_ 64 AB_Systemfehler 0 "kein_Fehler" 1 "Airbag_Systemfehler" ;
VAL_ 64 AB_Diagnose 0 "nicht_in_Diagnose" 1 "in_Diagnose" ;
VAL_ 64 AB_Stellgliedtest 0 "nicht_im_Stellgliedtest" 1 "Airbag_im_Stellgliedtest" ;
VAL_ 64 AB_Erh_Auf_VB 0 "keine_Anzeige" 1 "Beifahrerairbag_deaktiviert" 2 "Beifahrerairbag_aktiviert" 3 "nicht_definiert" ;
VAL_ 64 AB_Gurtwarn_VF 0 "keine_Warnung" 1 "Gurtwarnung_ausloesen" ;
VAL_ 64 AB_Gurtwarn_VB 0 "keine_Warnung" 1 "Gurtwarnung_ausloesen" ;
VAL_ 64 AB_Anzeige_Fussg 0 "keine_FSG_Aktion_ausgeloest" 1 "Motorhaube_offen" 2 "Systemfehler" ;
VAL_ 64 AB_Texte_AKS 0 "keine_AKS_Ausloesung" 1 "AKS_ausgeloest" 2 "AKS_Systemfehler" ;
VAL_ 64 AB_PAO_Leuchte_Anf 0 "Leuchte_ausschalten" 1 "Leuchte_einschalten" ;
VAL_ 64 AB_MKB_gueltig 0 "Multikollisionsbremsung_nicht_freigeschaltet" 1 "Multikollisionsbremsung_freigeschaltet" ;
VAL_ 64 AB_MKB_Anforderung 0 "Multikollisionsbremsung_nicht_angefordert" 1 "Multikollisionsbremsung_angefordert" ;
VAL_ 64 AB_Versorgungsspannung 0 "plausibel" 1 "unplausibel" ;
VAL_ 64 AB_Deaktivierung_HV 0 "keine_Deaktivierung" 1 "Deaktivierung_1" 2 "Deaktivierung_2" 3 "Deaktivierung_3" 4 "Deaktivierung_4" 5 "Deaktivierung_5" 6 "Deaktivierung_6" 7 "Fehler" ;
VAL_ 64 AB_EDR_Trigger 0 "No_Event" 1 "Start_Event" 2 "NonDeployment_Event" 3 "Deployment_Event" ;
VAL_ 64 AB_Belegung_VF 0 "nicht_verfuegbar" 1 "Fehler" 2 "nicht_belegt" 3 "belegt" ;
VAL_ 64 AB_Gurtschloss_FA_ext 0 "nicht_verbaut" 1 "reserviert" 2 "nicht_gesteckt" 3 "gesteckt" 4 "dauerhaft_nicht_gesteckt" 5 "dauerhaft_gesteckt" 6 "Init" 7 "Fehler" ;
VAL_ 64 AB_Gurtschloss_FA_ext_aktiv 0 "inaktiv" 1 "aktiv" ;
VAL_ 64 AB_eCS_Error 0 "keine_Anzeige" 1 "Anzeige_anfordern" ;
VAL_ 64 ASM_Masterzeit_02 255 "Init" ;
VAL_ 1312 LoGeWa_Event_Kombiwarnung 0 "Init" 1 "Unfall" 2 "Traktionsverlust" 3 "Panne" 4 "Sichtbehinderung" 5 "Aquaplaning" ;
VAL_ 1312 AB_Anforderung_eCall 0 "keine_Anforderung" 1 "Anforderung" ;
VAL_ 1312 AB_Anprall_Seite_Beifahrer 0 "kein_Anprall" 1 "Anprall_erkannt" ;
VAL_ 1312 AB_Anprall_Rollover 0 "kein_Anprall" 1 "Anprall_erkannt" ;
VAL_ 1312 AB_Anprall_FGS 0 "kein_Anprall" 1 "Anprall_erkannt" ;
VAL_ 1312 AB_Anprall_Front_Beifahrer 0 "kein_Anprall" 1 "Anprall_erkannt" ;
VAL_ 1312 AB_Anprall_Front_Fahrer 0 "kein_Anprall" 1 "Anprall_erkannt" ;
VAL_ 1312 AB_Anprall_Heck_Beifahrer 0 "kein_Anprall" 1 "Anprall_erkannt" ;
VAL_ 1312 AB_Anprall_Heck_Fahrer 0 "kein_Anprall" 1 "Anprall_erkannt" ;
VAL_ 1312 AB_Wickelklappung_Reihe2_MI 0 "nicht_verbaut" 1 "nicht_verfuegbar__Fehler_oder_Init" 2 "nicht_verriegelt" 3 "verriegelt" ;
VAL_ 1312 AB_Belegung_VB 0 "nicht_verfuegbar" 1 "Fehler" 2 "nicht_belegt" 3 "belegt" ;
VAL_ 1312 AB_Abschaltanf_SIH_BF 0 "Normalbetrieb" 1 "Abschaltung_angefordert" ;
VAL_ 1312 AB_Anprall_Seite_Fahrer 0 "kein_Anprall" 1 "Anprall_erkannt" ;
VAL_ 1312 SC_PAO_Schriftzug_Anf 0 "LED aus" 1 "LED an" 2 "LED blinken" 3 "reserviert" ;
VAL_ 1312 SC_PAO_ON_Anf 0 "LED aus" 1 "LED an" 2 "LED blinken" 3 "reserviert" ;
VAL_ 1312 SC_PAO_OFF_Anf 0 "LED aus" 1 "LED an" 2 "LED blinken" 3 "reserviert" ;
VAL_ 1312 AB_Crashschwere 0 "kein_Ereignis" 1 "Crashschwere_1" 2 "Crashschwere_2" 3 "Crashschwere_3" 4 "Crashschwere_4" 5 "Crashschwere_5" 6 "Crashschwere_2_bis_5" 7 "Fehler" ;
VAL_ 1312 AB_Anforderung_USM 0 "keine_Anforderung" 1 "Anforderung" ;
VAL_ 1312 AB_Gurtschloss_FA 0 "nicht_verbaut" 1 "nicht_verfügbar (Fehler oder Init)" 2 "nicht_gesteckt" 3 "gesteckt" ;
VAL_ 1312 AB_Gurtschloss_BF 0 "nicht_verbaut" 1 "nicht_verfügbar (Fehler oder Init)" 2 "nicht_gesteckt" 3 "gesteckt" ;
VAL_ 1312 AB_Gurtschloss_Reihe2_FA 0 "nicht_verbaut" 1 "nicht_verfügbar (Fehler oder Init)" 2 "nicht_gesteckt" 3 "gesteckt" ;
VAL_ 1312 AB_Gurtschloss_Reihe2_MI 0 "nicht_verbaut" 1 "nicht_verfügbar (Fehler oder Init)" 2 "nicht_gesteckt" 3 "gesteckt" ;
VAL_ 1312 AB_Gurtschloss_Reihe2_BF 0 "nicht_verbaut" 1 "nicht_verfügbar (Fehler oder Init)" 2 "nicht_gesteckt" 3 "gesteckt" ;
VAL_ 1312 AB_Gurtschloss_Reihe3_FA 0 "nicht_verbaut" 1 "nicht_verfügbar (Fehler oder Init)" 2 "nicht_gesteckt" 3 "gesteckt" ;
VAL_ 1312 AB_Gurtschloss_Reihe3_MI 0 "nicht_verbaut" 1 "nicht_verfügbar (Fehler oder Init)" 2 "nicht_gesteckt" 3 "gesteckt" ;
VAL_ 1312 AB_Gurtschloss_Reihe3_BF 0 "nicht_verbaut" 1 "nicht_verfügbar (Fehler oder Init)" 2 "nicht_gesteckt" 3 "gesteckt" ;
VAL_ 1312 AB_Sitzpos_Sens_FA 0 "nicht verfügbar" 1 "Fehler" 2 "Sitz nicht vorne" 3 "Sitz vorne" ;
VAL_ 1312 AB_Sitzpos_Sens_BF 0 "nicht verfügbar" 1 "Fehler" 2 "Sitz nicht vorne" 3 "Sitz vorne" ;
VAL_ 1312 AB_Wickelklappung_Reihe2_BF 0 "nicht_verbaut" 1 "nicht_verfuegbar__Fehler_oder_Init" 2 "nicht_verriegelt" 3 "verriegelt" ;
VAL_ 1312 AB_Wickelklappung_Reihe2_FA 0 "nicht_verbaut" 1 "nicht_verfuegbar__Fehler_oder_Init" 2 "nicht_verriegelt" 3 "verriegelt" ;
VAL_ 2331596049 AB_eCS_Aktuatortest_Reihe3_BF 0 "Keine_Aktion" 1 "Verriegelt" 2 "Entriegelt" 3 "Unplausibel" ;
VAL_ 2331596049 AB_eCS_Aktuatortest_Reihe3_FA 0 "Keine_Aktion" 1 "Verriegelt" 2 "Entriegelt" 3 "Unplausibel" ;
VAL_ 2331596049 AB_eCS_Aktuatortest_FA 0 "Keine_Aktion" 1 "Verriegelt" 2 "Entriegelt" 3 "Unplausibel" ;
VAL_ 2331596049 AB_eCS_Aktuatortest_BF 0 "Keine_Aktion" 1 "Verriegelt" 2 "Entriegelt" 3 "Unplausibel" ;
VAL_ 2331596049 AB_eCS_Aktuatortest_Reihe2_FA 0 "Keine_Aktion" 1 "Verriegelt" 2 "Entriegelt" 3 "Unplausibel" ;
VAL_ 2331596049 AB_eCS_Aktuatortest_Reihe2_BF 0 "Keine_Aktion" 1 "Verriegelt" 2 "Entriegelt" 3 "Unplausibel" ;
VAL_ 2331596048 eCS_Status 0 "Init" 1 "verriegelt" 2 "entriegelt" 3 "Fehler" ;
VAL_ 2331596048 eCS_Stoerung 0 "keine_Stoerung" 1 "Stoerung" ;
VAL_ 2331596048 eCS_HW_defekt 0 "nicht_defekt" 1 "Defekt" ;
VAL_ 2331596048 eCS_Gurtschloss_Status_Reihe2_FA 0 "nicht_verbaut" 1 "nicht_verfuegbar_Fehler_o_Init" 2 "nicht_gesteckt" 3 "gesteckt" ;
VAL_ 2331596048 eCS_Gurtschloss_Status_Reihe2_BF 0 "nicht_verbaut" 1 "nicht_verfuegbar_Fehler_o_Init" 2 "nicht_gesteckt" 3 "gesteckt" ;
VAL_ 2331596048 eCS_SBS_Belegung_Reihe2_FA 0 "nicht_verfuegbar" 1 "Kurzschluss_nach_Masse" 2 "nicht_belegt" 3 "belegt" ;
VAL_ 2331596048 eCS_SBS_Belegung_Reihe2_BF 0 "nicht_verfuegbar" 1 "Kurzschluss_nach_Masse" 2 "nicht_belegt" 3 "belegt" ;
